# MDR1986VK01 register map
File version: 1.0.2
Registers are 32-bit, read-write, no defined reset value unless marked. A register's access mark holds for its fields unless they carry their own. Offsets are from the block's base; [hi:lo] are bit positions; 'fields as' and 'values as' point back to an identical list.

## MDR_CAN0 — MDR_CAN0 description
Base 0x4008B000
Same registers: MDR_CAN1 0x4008C000
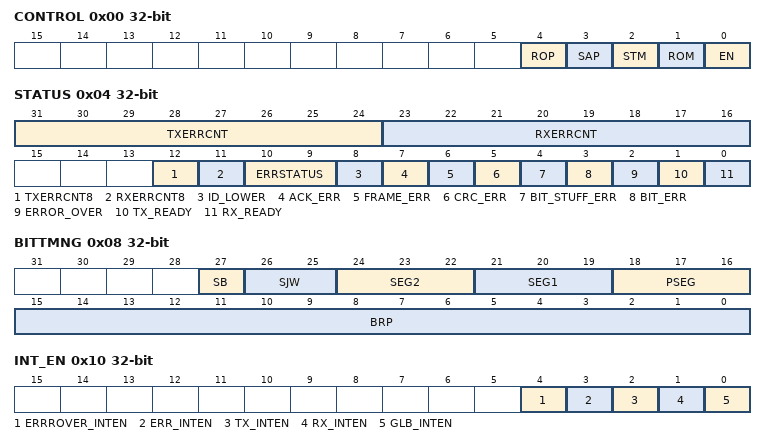
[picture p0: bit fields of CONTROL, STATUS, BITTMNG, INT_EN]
0x00 CONTROL — CONTROL description
  [4] ROP — ROP description
  [3] SAP — SAP description
  [2] STM — STM description
  [1] ROM — ROM description
  [0] EN — EN description
0x04 STATUS — STATUS description
  [31:24] TXERRCNT — TXERRCNT description
  [23:16] RXERRCNT — RXERRCNT description
  [12] TXERRCNT8 — TXERRCNT8 description
  [11] RXERRCNT8 — RXERRCNT8 description
  [10:9] ERRSTATUS — ERRSTATUS description
  [8] ID_LOWER — ID_LOWER description
  [7] ACK_ERR — ACK_ERR description
  [6] FRAME_ERR — FRAME_ERR description
  [5] CRC_ERR — CRC_ERR description
  [4] BIT_STUFF_ERR — BIT_STUFF_ERR description
  [3] BIT_ERR — BIT_ERR description
  [2] ERROR_OVER — ERROR_OVER description
  [1] TX_READY — TX_READY description
  [0] RX_READY — RX_READY description
0x08 BITTMNG — BITTMNG description
  [27] SB — SB description
  [26:25] SJW — SJW description
  [24:22] SEG2 — SEG2 description
  [21:19] SEG1 — SEG1 description
  [18:16] PSEG — PSEG description
  [15:0] BRP — BRP description
0x10 INT_EN — INT_EN description
  [4] ERRROVER_INTEN — ERRROVER_INTEN description
  [3] ERR_INTEN — ERR_INTEN description
  [2] TX_INTEN — TX_INTEN description
  [1] RX_INTEN — RX_INTEN description
  [0] GLB_INTEN — GLB_INTEN description
0x1C OVER — OVER description
  [7:0] ERRORMAX — ERRORMAX description
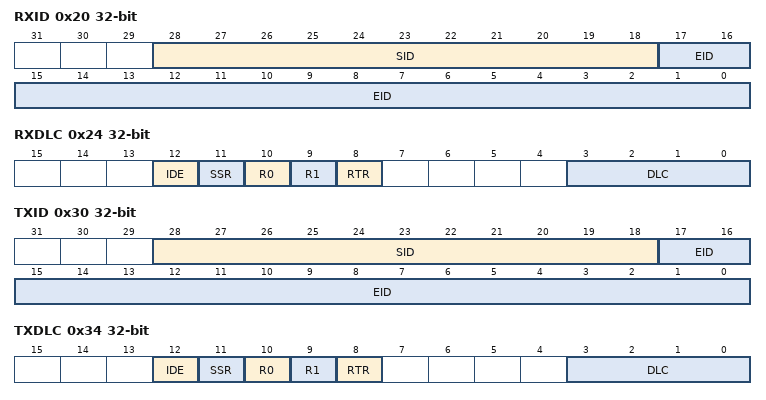
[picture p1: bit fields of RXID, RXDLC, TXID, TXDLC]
0x20 RXID — RXID description
  [28:18] SID — SID description
  [17:0] EID — EID description
0x24 RXDLC — RXDLC description
  [12] IDE — IDE description
  [11] SSR — SSR description
  [10] R0 — R0 description
  [9] R1 — R1 description
  [8] RTR — RTR description
  [3:0] DLC — DLC description
0x28 RXDATAL — RXDATAL description
0x2C RXDATAH — RXDATAH description
0x30 TXID — TXID description
  [28:18] SID — SID description
  [17:0] EID — EID description
0x34 TXDLC — TXDLC description
  fields as RXDLC
0x38 DATAL — DATAL description
0x3C DATAH — DATAH description
0x40 BUF_CON0 — BUF_CON0 description
0xC0 INT_RX — INT_RX description
0xC4 RX — RX description
0xC8 INT_TX — INT_TX description
0xCC TX — TX description

## MDR_UART0 — MDR_UART0 description
Base 0x4008D000
Same registers: MDR_UART1 0x4008E000, MDR_UART2 0x4008F000, MDR_UART3 0x40090000
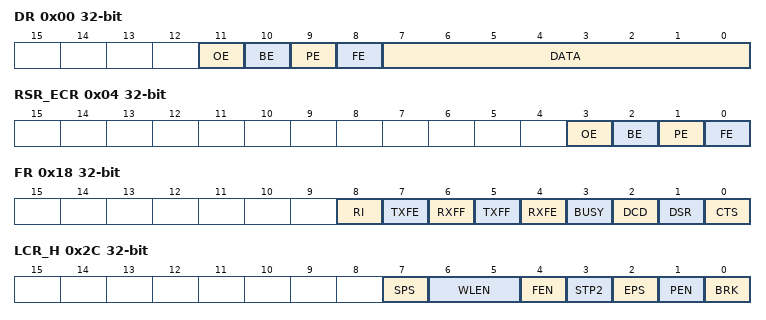
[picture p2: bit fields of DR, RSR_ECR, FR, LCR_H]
0x00 DR — DR description
  [11] OE — OE description
  [10] BE — BE description
  [9] PE — PE description
  [8] FE — FE description
  [7:0] DATA — DATA description
0x04 RSR_ECR — RSR_ECR description
  [3] OE — OE description
  [2] BE — BE description
  [1] PE — PE description
  [0] FE — FE description
0x18 FR — FR description
  [8] RI — RI description
  [7] TXFE — TXFE description
  [6] RXFF — RXFF description
  [5] TXFF — TXFF description
  [4] RXFE — RXFE description
  [3] BUSY — BUSY description
  [2] DCD — DCD description
  [1] DSR — DSR description
  [0] CTS — CTS description
0x20 ILPR — ILPR description
  [7:0] DVSR — DVSR description
0x24 IBRD — IBRD description
  [15:0] BAUDDIV_INT — BAUDDIV_INT description
0x28 FBRD — FBRD description
  [5:0] BAUDDIV_FRAC — BAUDDIV_FRAC description
0x2C LCR_H — LCR_H description
  [7] SPS — SPS description
  [6:5] WLEN — WLEN description
  [4] FEN — FEN description
  [3] STP2 — STP2 description
  [2] EPS — EPS description
  [1] PEN — PEN description
  [0] BRK — BRK description
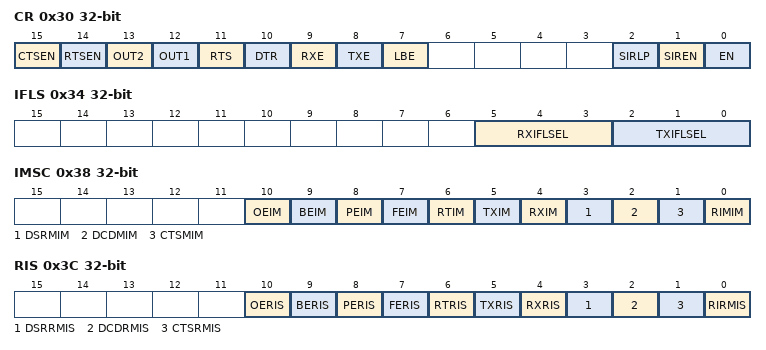
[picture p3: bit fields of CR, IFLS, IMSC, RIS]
0x30 CR — CR description
  [15] CTSEN — CTSEN description
  [14] RTSEN — RTSEN description
  [13] OUT2 — OUT2 description
  [12] OUT1 — OUT1 description
  [11] RTS — RTS description
  [10] DTR — DTR description
  [9] RXE — RXE description
  [8] TXE — TXE description
  [7] LBE — LBE description
  [2] SIRLP — SIRLP description
  [1] SIREN — SIREN description
  [0] EN — EN description
0x34 IFLS — IFLS description
  [5:3] RXIFLSEL — RXIFLSEL description
  [2:0] TXIFLSEL — TXIFLSEL description
0x38 IMSC — IMSC description
  [10] OEIM — OEIM description
  [9] BEIM — BEIM description
  [8] PEIM — PEIM description
  [7] FEIM — FEIM description
  [6] RTIM — RTIM description
  [5] TXIM — TXIM description
  [4] RXIM — RXIM description
  [3] DSRMIM — DSRMIM description
  [2] DCDMIM — DCDMIM description
  [1] CTSMIM — CTSMIM description
  [0] RIMIM — RIMIM description
0x3C RIS — RIS description
  [10] OERIS — OERIS description
  [9] BERIS — BERIS description
  [8] PERIS — PERIS description
  [7] FERIS — FERIS description
  [6] RTRIS — RTRIS description
  [5] TXRIS — TXRIS description
  [4] RXRIS — RXRIS description
  [3] DSRRMIS — DSRRMIS description
  [2] DCDRMIS — DCDRMIS description
  [1] CTSRMIS — CTSRMIS description
  [0] RIRMIS — RIRMIS description
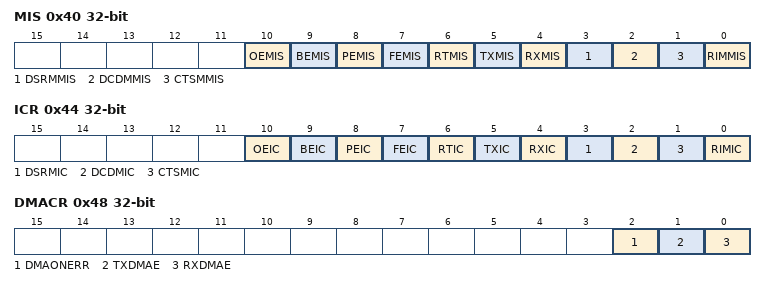
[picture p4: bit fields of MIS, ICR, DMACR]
0x40 MIS — MIS description
  [10] OEMIS — OEMIS description
  [9] BEMIS — BEMIS description
  [8] PEMIS — PEMIS description
  [7] FEMIS — FEMIS description
  [6] RTMIS — RTMIS description
  [5] TXMIS — TXMIS description
  [4] RXMIS — RXMIS description
  [3] DSRMMIS — DSRMMIS description
  [2] DCDMMIS — DCDMMIS description
  [1] CTSMMIS — CTSMMIS description
  [0] RIMMIS — RIMMIS description
0x44 ICR — ICR description
  [10] OEIC — OEIC description
  [9] BEIC — BEIC description
  [8] PEIC — PEIC description
  [7] FEIC — FEIC description
  [6] RTIC — RTIC description
  [5] TXIC — TXIC description
  [4] RXIC — RXIC description
  [3] DSRMIC — DSRMIC description
  [2] DCDMIC — DCDMIC description
  [1] CTSMIC — CTSMIC description
  [0] RIMIC — RIMIC description
0x48 DMACR — DMACR description
  [2] DMAONERR — DMAONERR description
  [1] TXDMAE — TXDMAE description
  [0] RXDMAE — RXDMAE description
